# AT90PWM81 register map
Vendor: Atmel; File version: 1.0
CPU: other r0p0, little endian, no MPU, no FPU, 4 interrupt priority bits
Registers are 8-bit, read-write, reset 0x0 unless marked. A register's access mark holds for its fields unless they carry their own. Offsets are from the block's base; [hi:lo] are bit positions.

## PSC2 — Power Stage Controller
Base 0x00800033
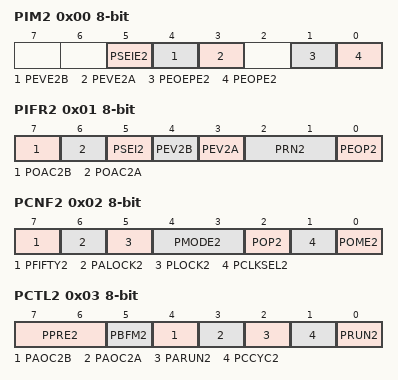
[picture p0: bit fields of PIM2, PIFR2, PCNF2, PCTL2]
0x00 PIM2 — PSC2 Interrupt Mask Register
  [5] PSEIE2 — PSC 2 Synchro Error Interrupt Enable
  [4] PEVE2B — External Event B Interrupt Enable
  [3] PEVE2A — External Event A Interrupt Enable
  [1] PEOEPE2 — End of Enhanced Cycle Interrupt Enable
  [0] PEOPE2 — End of Cycle Interrupt Enable
0x01 PIFR2 — PSC2 Interrupt Flag Register
  [7] POAC2B — PSC 2 Output A Activity
  [6] POAC2A — PSC 2 Output A Activity
  [5] PSEI2 — PSC 2 Synchro Error Interrupt
  [4] PEV2B — External Event B Interrupt
  [3] PEV2A — External Event A Interrupt
  [2:1] PRN2 — Ramp Number
  [0] PEOP2 — End of PSC2 Interrupt
0x02 PCNF2 — PSC 2 Configuration Register
  [7] PFIFTY2 — PSC 2 Fifty
  [6] PALOCK2 — PSC 2 Autolock
  [5] PLOCK2 — PSC 2 Lock
  [4:3] PMODE2 — PSC 2 Mode
  [2] POP2 — PSC 2 Output Polarity
  [1] PCLKSEL2 — PSC 2 Input Clock Select
  [0] POME2 — PSC 2 Output Matrix Enable
0x03 PCTL2 — PSC 2 Control Register
  [7:6] PPRE2 — PSC 2 Prescaler Selects
  [5] PBFM2 — Balance Flank Width Modulation
  [4] PAOC2B — PSC 2 Asynchronous Output Control B
  [3] PAOC2A — PSC 2 Asynchronous Output Control A
  [2] PARUN2 — PSC2 Auto Run
  [1] PCCYC2 — PSC2 Complete Cycle
  [0] PRUN2 — PSC 2 Run
0x13 OCR2SB 16-bit (reset mask 0xFF) — Output Compare SB Register
  [11:0] OCR2SB — Output Compare 2 SB
0x15 OCR2RB 16-bit (reset mask 0xFF) — Output Compare RB Register
  [15:0] OCR2RB — Output Compare 2 RB
0x1B OCR2RA 16-bit (reset mask 0xFF) — Output Compare RA Register
  [11:0] OCR2RA — Output Compare 2 RA
0x31 OCR2SA 16-bit (reset mask 0xFF) — Output Compare SA Register
  [11:0] OCR2SA — Output Compare 2 SA
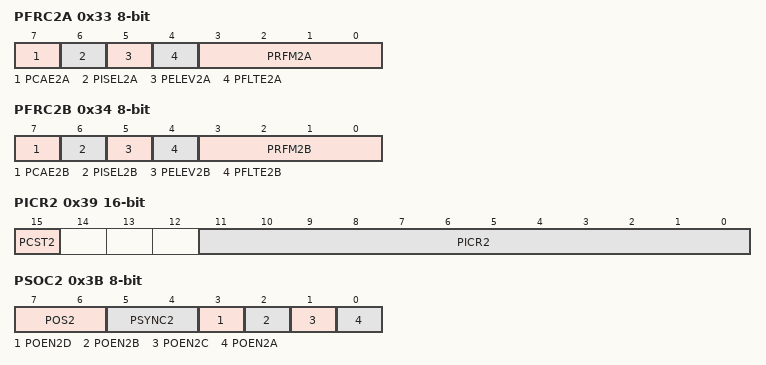
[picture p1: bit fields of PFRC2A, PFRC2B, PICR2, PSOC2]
0x33 PFRC2A — PSC 2 Input B Control
  [7] PCAE2A — PSC 2 Capture Enable Input Part A
  [6] PISEL2A — PSC 2 Input Select for Part A
  [5] PELEV2A — PSC 2 Edge Level Selector on Input Part A
  [4] PFLTE2A — PSC 2 Filter Enable on Input Part A
  [3:0] PRFM2A — PSC 2 Retrigger and Fault Mode for Part A
0x34 PFRC2B — PSC 2 Input B Control
  [7] PCAE2B — PSC 2 Capture Enable Input Part B
  [6] PISEL2B — PSC 2 Input Select for Part B
  [5] PELEV2B — PSC 2 Edge Level Selector on Input Part B
  [4] PFLTE2B — PSC 2 Filter Enable on Input Part B
  [3:0] PRFM2B — PSC 2 Retrigger and Fault Mode for Part B
0x39 PICR2 16-bit (reset mask 0xFF) — PSC 2 Input Capture Register
  [15] PCST2 — PSC 2 Capture Software Trigger Bit
  [11:0] PICR2 — PSC 2 Input Capture Bytes
0x3B PSOC2 — PSC2 Synchro and Output Configuration
  [7:6] POS2 — PSC 2 Output 23 Select
  [5:4] PSYNC2 — Synchronization Out for ADC Selection
  [3] POEN2D — PSCOUT23 Output Enable
  [2] POEN2B — PSCOUT21 Output Enable
  [1] POEN2C — PSCOUT22 Output Enable
  [0] POEN2A — PSCOUT20 Output Enable
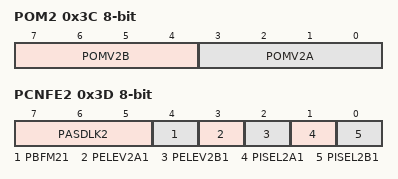
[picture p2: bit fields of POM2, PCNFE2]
0x3C POM2 — PSC 2 Output Matrix
  [7:4] POMV2B — Output Matrix Output B Ramps
  [3:0] POMV2A — Output Matrix Output A Ramps
0x3D PCNFE2 — PSC 2 Enhanced Configuration Register
  [7:5] PASDLK2, [4] PBFM21, [3] PELEV2A1, [2] PELEV2B1, [1] PISEL2A1, [0] PISEL2B1
0x3E PASDLY2 — Analog Synchronization Delay Register
  [7:0] PASDLY2 — Analog Synchronization Delay bits

## SPI — Serial Peripheral Interface
Base 0x00800037
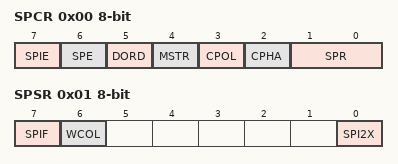
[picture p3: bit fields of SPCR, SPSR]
0x00 SPCR — SPI Control Register
  [7] SPIE — SPI Interrupt Enable
  [6] SPE — SPI Enable
  [5] DORD — Data Order
  [4] MSTR — Master/Slave Select
  [3] CPOL — Clock polarity
  [2] CPHA — Clock Phase
  [1:0] SPR — SPI Clock Rate Selects
    0=FOSC_4; 1=FOSC_16; 3=FOSC_128
0x01 SPSR — SPI Status Register (read-only for debugger)
  [7] SPIF — SPI Interrupt Flag
  [6] WCOL — Write Collision Flag
  [0] SPI2X — Double SPI Speed Bit
0x1F SPDR — SPI Data Register (write-only for debugger)
  [7:0] SPD — SPI Data bits

## TC1 — Timer/Counter, 16-bit
Base 0x00800021
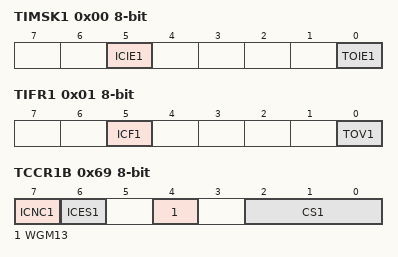
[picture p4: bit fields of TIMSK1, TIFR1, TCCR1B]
0x00 TIMSK1 — Timer/Counter Interrupt Mask Register
  [5] ICIE1 — Timer/Counter1 Input Capture Interrupt Enable
  [0] TOIE1 — Timer/Counter1 Overflow Interrupt Enable
0x01 TIFR1 — Timer/Counter Interrupt Flag register (read-only for debugger)
  [5] ICF1 — Input Capture Flag 1
  [0] TOV1 — Timer/Counter1 Overflow Flag
0x39 TCNT1 16-bit (reset mask 0xFF) — Timer/Counter1 Bytes
  [15:0] TCNT1 — Timer/Counter 1 bits
0x69 TCCR1B — Timer/Counter1 Control Register B
  [7] ICNC1 — Input Capture 1 Noise Canceler
  [6] ICES1 — Input Capture 1 Edge Select
  [4] WGM13 — Waveform Generation Mode
  [2:0] CS1 — Prescaler source of Timer/Counter 1
    0=NO_CLOCK_SOURCE_STOPPED; 1=RUNNING_NO_PRESCALING; 2=RUNNING_CLK_8; 3=RUNNING_CLK_64; 4=RUNNING_CLK_256; 5=RUNNING_CLK_1024; 6=RUNNING_EXTCLK_TN_FALLING_EDGE; 7=RUNNING_EXTCLK_TN_RISING_EDGE
0x6B ICR1 16-bit (reset mask 0xFF) — Timer/Counter1 Input Capture Register Bytes
  [15:0] ICR1 — Timer/Counter1 Input Capture bits

## WDT — Watchdog Timer
Base 0x00800082
0x00 WDTCSR — Watchdog Timer Control Register (read-only for debugger)
  [7] WDIF — Watchdog Timeout Interrupt Flag
  [6] WDIE — Watchdog Timeout Interrupt Enable
  [4] WDCE — Watchdog Change Enable
  [3] WDE — Watch Dog Enable
  [5:0] WDP — Watchdog Timer Prescaler Bits
    0=OSCILLATOR_CYCLES_2K; 1=OSCILLATOR_CYCLES_4K; 2=OSCILLATOR_CYCLES_8K; 3=OSCILLATOR_CYCLES_16K; 4=OSCILLATOR_CYCLES_32K; 5=OSCILLATOR_CYCLES_64K; 6=OSCILLATOR_CYCLES_128K; 7=OSCILLATOR_CYCLES_256K
